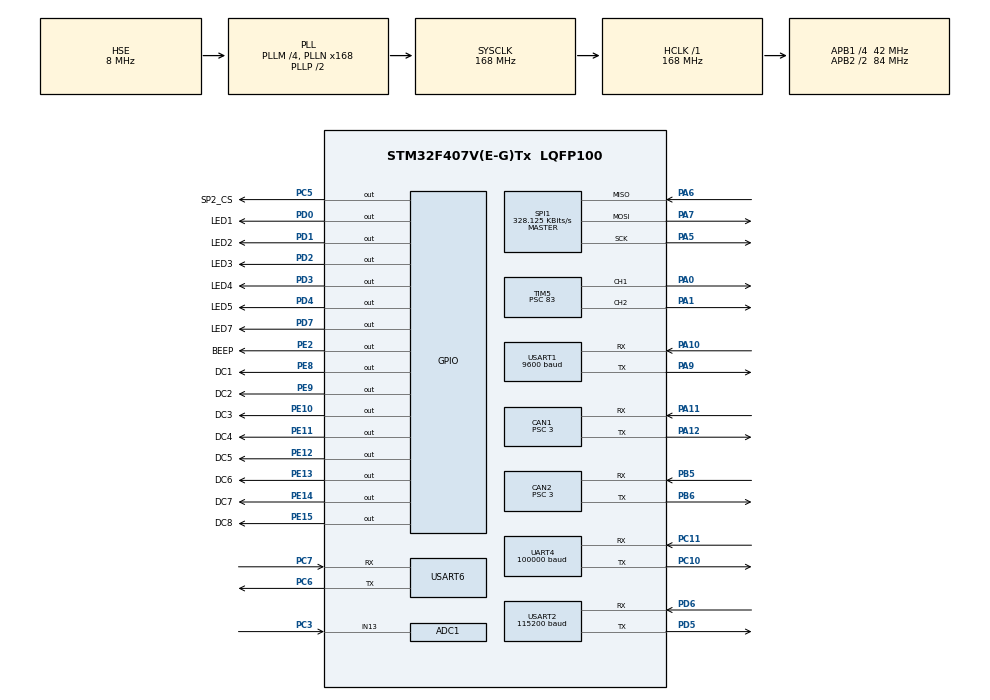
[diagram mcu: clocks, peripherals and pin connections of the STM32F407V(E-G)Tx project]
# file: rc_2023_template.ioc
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ADC1.Channel-0\#ChannelRegularConversion=ADC_CHANNEL_13
ADC1.ContinuousConvMode=DISABLE
ADC1.DMAContinuousRequests=DISABLE
ADC1.NbrOfConversionFlag=1
ADC1.Rank-0\#ChannelRegularConversion=1
ADC1.SamplingTime-0\#ChannelRegularConversion=ADC_SAMPLETIME_3CYCLES
ADC1.master=1
CAN1.ABOM=ENABLE
CAN1.BS1=CAN_BS1_9TQ
CAN1.BS2=CAN_BS2_4TQ
CAN1.CalculateBaudRate=1000000
CAN1.CalculateTimeBit=1000
CAN1.CalculateTimeQuantum=71.42857142857143
CAN1.NART=ENABLE
CAN1.Prescaler=3
CAN2.ABOM=ENABLE
CAN2.BS1=CAN_BS1_9TQ
CAN2.BS2=CAN_BS2_4TQ
CAN2.CalculateBaudRate=1000000
CAN2.CalculateTimeBit=1000
CAN2.CalculateTimeQuantum=71.42857142857143
CAN2.NART=ENABLE
CAN2.Prescaler=3
Dma.Request0=USART1_RX
Dma.Request1=USART1_TX
Dma.Request2=UART4_RX
Dma.Request3=USART2_RX
Dma.Request4=USART2_TX
Dma.Request5=USART6_RX
Dma.Request6=USART6_TX
Dma.UART4_RX.2.Direction=DMA_PERIPH_TO_MEMORY
Dma.UART4_RX.2.FIFOMode=DMA_FIFOMODE_DISABLE
Dma.UART4_RX.2.Instance=DMA1_Stream2
Dma.UART4_RX.2.MemDataAlignment=DMA_MDATAALIGN_BYTE
Dma.UART4_RX.2.MemInc=DMA_MINC_ENABLE
Dma.UART4_RX.2.Mode=DMA_CIRCULAR
Dma.UART4_RX.2.PeriphDataAlignment=DMA_PDATAALIGN_BYTE
Dma.UART4_RX.2.PeriphInc=DMA_PINC_DISABLE
Dma.UART4_RX.2.Priority=DMA_PRIORITY_VERY_HIGH
Dma.USART1_RX.0.Direction=DMA_PERIPH_TO_MEMORY
Dma.USART1_RX.0.FIFOMode=DMA_FIFOMODE_DISABLE
Dma.USART1_RX.0.Instance=DMA2_Stream2
Dma.USART1_RX.0.MemDataAlignment=DMA_MDATAALIGN_BYTE
Dma.USART1_RX.0.MemInc=DMA_MINC_ENABLE
Dma.USART1_RX.0.Mode=DMA_CIRCULAR
Dma.USART1_RX.0.PeriphDataAlignment=DMA_PDATAALIGN_BYTE
Dma.USART1_RX.0.PeriphInc=DMA_PINC_DISABLE
Dma.USART1_RX.0.Priority=DMA_PRIORITY_VERY_HIGH
Dma.USART1_TX.1.Direction=DMA_MEMORY_TO_PERIPH
Dma.USART1_TX.1.FIFOMode=DMA_FIFOMODE_DISABLE
Dma.USART1_TX.1.Instance=DMA2_Stream7
Dma.USART1_TX.1.MemDataAlignment=DMA_MDATAALIGN_BYTE
Dma.USART1_TX.1.MemInc=DMA_MINC_ENABLE
Dma.USART1_TX.1.Mode=DMA_NORMAL
Dma.USART1_TX.1.PeriphDataAlignment=DMA_PDATAALIGN_BYTE
Dma.USART1_TX.1.PeriphInc=DMA_PINC_DISABLE
Dma.USART1_TX.1.Priority=DMA_PRIORITY_HIGH
Dma.USART2_RX.3.Direction=DMA_PERIPH_TO_MEMORY
Dma.USART2_RX.3.FIFOMode=DMA_FIFOMODE_DISABLE
Dma.USART2_RX.3.Instance=DMA1_Stream5
Dma.USART2_RX.3.MemDataAlignment=DMA_MDATAALIGN_BYTE
Dma.USART2_RX.3.MemInc=DMA_MINC_ENABLE
Dma.USART2_RX.3.Mode=DMA_CIRCULAR
Dma.USART2_RX.3.PeriphDataAlignment=DMA_PDATAALIGN_BYTE
Dma.USART2_RX.3.PeriphInc=DMA_PINC_DISABLE
Dma.USART2_RX.3.Priority=DMA_PRIORITY_VERY_HIGH
Dma.USART2_TX.4.Direction=DMA_MEMORY_TO_PERIPH
Dma.USART2_TX.4.FIFOMode=DMA_FIFOMODE_DISABLE
Dma.USART2_TX.4.Instance=DMA1_Stream6
Dma.USART2_TX.4.MemDataAlignment=DMA_MDATAALIGN_BYTE
Dma.USART2_TX.4.MemInc=DMA_MINC_ENABLE
Dma.USART2_TX.4.Mode=DMA_NORMAL
Dma.USART2_TX.4.PeriphDataAlignment=DMA_PDATAALIGN_BYTE
Dma.USART2_TX.4.PeriphInc=DMA_PINC_DISABLE
Dma.USART2_TX.4.Priority=DMA_PRIORITY_HIGH
Dma.USART6_RX.5.Direction=DMA_PERIPH_TO_MEMORY
Dma.USART6_RX.5.FIFOMode=DMA_FIFOMODE_DISABLE
Dma.USART6_RX.5.Instance=DMA2_Stream1
Dma.USART6_RX.5.MemDataAlignment=DMA_MDATAALIGN_BYTE
Dma.USART6_RX.5.MemInc=DMA_MINC_ENABLE
Dma.USART6_RX.5.Mode=DMA_NORMAL
Dma.USART6_RX.5.PeriphDataAlignment=DMA_PDATAALIGN_BYTE
Dma.USART6_RX.5.PeriphInc=DMA_PINC_DISABLE
Dma.USART6_RX.5.Priority=DMA_PRIORITY_VERY_HIGH
Dma.USART6_TX.6.Direction=DMA_MEMORY_TO_PERIPH
Dma.USART6_TX.6.FIFOMode=DMA_FIFOMODE_DISABLE
Dma.USART6_TX.6.Instance=DMA2_Stream6
Dma.USART6_TX.6.MemDataAlignment=DMA_MDATAALIGN_BYTE
Dma.USART6_TX.6.MemInc=DMA_MINC_ENABLE
Dma.USART6_TX.6.Mode=DMA_NORMAL
Dma.USART6_TX.6.PeriphDataAlignment=DMA_PDATAALIGN_BYTE
Dma.USART6_TX.6.PeriphInc=DMA_PINC_DISABLE
Dma.USART6_TX.6.Priority=DMA_PRIORITY_HIGH
FREERTOS.INCLUDE_eTaskGetState=1
FREERTOS.INCLUDE_vTaskDelayUntil=1
FREERTOS.Tasks01=defaultTask,0,128,StartDefaultTask,Default,NULL,Dynamic,NULL,NULL
FREERTOS.configGENERATE_RUN_TIME_STATS=0
FREERTOS.configMINIMAL_STACK_SIZE=64
FREERTOS.configUSE_IDLE_HOOK=1
FREERTOS.configUSE_TRACE_FACILITY=1
Mcu.Family=STM32F4
Mcu.Name=STM32F407V(E-G)Tx
Mcu.Package=LQFP100
NVIC.CAN1_RX0_IRQn=true\:5\:0\:false\:false\:true\:true\:true\:true\:true
NVIC.CAN1_RX1_IRQn=true\:5\:0\:false\:false\:true\:true\:true\:true\:true
NVIC.CAN2_RX0_IRQn=true\:5\:0\:false\:false\:true\:true\:true\:true\:true
NVIC.CAN2_RX1_IRQn=true\:5\:0\:false\:false\:true\:true\:true\:true\:true
NVIC.DMA1_Stream2_IRQn=true\:5\:0\:false\:false\:true\:true\:false\:true\:true
NVIC.DMA1_Stream5_IRQn=true\:5\:0\:false\:false\:true\:true\:false\:true\:true
NVIC.DMA1_Stream6_IRQn=true\:5\:0\:false\:false\:true\:true\:false\:true\:true
NVIC.DMA2_Stream1_IRQn=true\:5\:0\:false\:false\:true\:true\:false\:true\:true
NVIC.DMA2_Stream2_IRQn=true\:5\:0\:false\:false\:true\:true\:false\:true\:true
NVIC.DMA2_Stream6_IRQn=true\:5\:0\:false\:false\:true\:true\:false\:true\:true
NVIC.DMA2_Stream7_IRQn=true\:5\:0\:false\:false\:true\:true\:false\:true\:true
NVIC.PriorityGroup=NVIC_PRIORITYGROUP_4
NVIC.TIM1_UP_TIM10_IRQn=true\:5\:0\:false\:false\:true\:true\:true\:true\:true
NVIC.TIM6_DAC_IRQn=true\:15\:0\:false\:false\:true\:false\:false\:true\:true
NVIC.TIM7_IRQn=true\:5\:0\:true\:false\:true\:true\:true\:true\:true
NVIC.TimeBase=TIM6_DAC_IRQn
NVIC.TimeBaseIP=TIM6
NVIC.UART4_IRQn=true\:5\:0\:false\:false\:true\:true\:true\:true\:true
NVIC.USART1_IRQn=true\:5\:0\:true\:false\:true\:true\:true\:true\:true
NVIC.USART2_IRQn=true\:5\:0\:false\:false\:true\:true\:true\:true\:true
NVIC.USART6_IRQn=true\:5\:0\:false\:false\:true\:true\:true\:true\:true
PA0-WKUP.Signal=S_TIM5_CH1
PA1.Signal=S_TIM5_CH2
PA10.Mode=Asynchronous
PA10.Signal=USART1_RX
PA11.Mode=CAN_Activate
PA11.Signal=CAN1_RX
PA12.Mode=CAN_Activate
PA12.Signal=CAN1_TX
PA13.Mode=Serial_Wire
PA13.Signal=SYS_JTMS-SWDIO
PA14.Mode=Serial_Wire
PA14.Signal=SYS_JTCK-SWCLK
PA5.Mode=Full_Duplex_Master
PA5.Signal=SPI1_SCK
PA6.Mode=Full_Duplex_Master
PA6.Signal=SPI1_MISO
PA7.Mode=Full_Duplex_Master
PA7.Signal=SPI1_MOSI
PA9.Mode=Asynchronous
PA9.Signal=USART1_TX
PB5.Mode=CAN_Activate
PB5.Signal=CAN2_RX
PB6.Mode=CAN_Activate
PB6.Signal=CAN2_TX
PC10.Mode=Asynchronous
PC10.Signal=UART4_TX
PC11.GPIO_PuPd=GPIO_PULLUP
PC11.GPIO_Speed=GPIO_SPEED_FREQ_VERY_HIGH
PC11.Mode=Asynchronous
PC11.Signal=UART4_RX
PC3.Signal=ADCx_IN13
PC5.GPIO_Label=SP2_CS
PC5.GPIO_ModeDefaultOutputPP=GPIO_MODE_OUTPUT_PP
PC5.GPIO_PuPd=GPIO_PULLUP
PC5.GPIO_Speed=GPIO_SPEED_FREQ_HIGH
PC5.PinState=GPIO_PIN_RESET
PC5.Signal=GPIO_Output
PC6.Mode=Asynchronous
PC6.Signal=USART6_TX
PC7.Mode=Asynchronous
PC7.Signal=USART6_RX
PD0.GPIO_Label=LED1
PD0.GPIO_PuPd=GPIO_PULLUP
PD0.GPIO_Speed=GPIO_SPEED_FREQ_HIGH
PD0.PinState=GPIO_PIN_SET
PD0.Signal=GPIO_Output
PD1.GPIO_Label=LED2
PD1.GPIO_PuPd=GPIO_PULLUP
PD1.GPIO_Speed=GPIO_SPEED_FREQ_HIGH
PD1.PinState=GPIO_PIN_SET
PD1.Signal=GPIO_Output
PD2.GPIO_Label=LED3
PD2.GPIO_PuPd=GPIO_PULLUP
PD2.GPIO_Speed=GPIO_SPEED_FREQ_HIGH
PD2.PinState=GPIO_PIN_SET
PD2.Signal=GPIO_Output
PD3.GPIO_Label=LED4
PD3.GPIO_PuPd=GPIO_PULLUP
PD3.GPIO_Speed=GPIO_SPEED_FREQ_HIGH
PD3.PinState=GPIO_PIN_SET
PD3.Signal=GPIO_Output
PD4.GPIO_Label=LED5
PD4.GPIO_ModeDefaultOutputPP=GPIO_MODE_OUTPUT_PP
PD4.GPIO_PuPd=GPIO_PULLUP
PD4.GPIO_Speed=GPIO_SPEED_FREQ_HIGH
PD4.PinState=GPIO_PIN_SET
PD4.Signal=GPIO_Output
PD5.Mode=Asynchronous
PD5.Signal=USART2_TX
PD6.Mode=Asynchronous
PD6.Signal=USART2_RX
PD7.GPIO_Label=LED7
PD7.GPIO_ModeDefaultOutputPP=GPIO_MODE_OUTPUT_PP
PD7.GPIO_PuPd=GPIO_PULLUP
PD7.GPIO_Speed=GPIO_SPEED_FREQ_HIGH
PD7.PinState=GPIO_PIN_SET
PD7.Signal=GPIO_Output
PE10.GPIO_Label=DC3
PE10.GPIO_ModeDefaultOutputPP=GPIO_MODE_OUTPUT_PP
PE10.GPIO_PuPd=GPIO_PULLUP
PE10.GPIO_Speed=GPIO_SPEED_FREQ_HIGH
PE10.PinState=GPIO_PIN_SET
PE10.Signal=GPIO_Output
PE11.GPIO_Label=DC4
PE11.GPIO_ModeDefaultOutputPP=GPIO_MODE_OUTPUT_PP
PE11.GPIO_PuPd=GPIO_PULLUP
PE11.GPIO_Speed=GPIO_SPEED_FREQ_HIGH
PE11.PinState=GPIO_PIN_SET
PE11.Signal=GPIO_Output
PE12.GPIO_Label=DC5
PE12.GPIO_ModeDefaultOutputPP=GPIO_MODE_OUTPUT_PP
PE12.GPIO_PuPd=GPIO_PULLUP
PE12.GPIO_Speed=GPIO_SPEED_FREQ_HIGH
PE12.PinState=GPIO_PIN_SET
PE12.Signal=GPIO_Output
PE13.GPIO_Label=DC6
PE13.GPIO_ModeDefaultOutputPP=GPIO_MODE_OUTPUT_PP
PE13.GPIO_PuPd=GPIO_PULLUP
PE13.GPIO_Speed=GPIO_SPEED_FREQ_HIGH
PE13.PinState=GPIO_PIN_SET
PE13.Signal=GPIO_Output
PE14.GPIO_Label=DC7
PE14.GPIO_ModeDefaultOutputPP=GPIO_MODE_OUTPUT_PP
PE14.GPIO_PuPd=GPIO_PULLUP
PE14.GPIO_Speed=GPIO_SPEED_FREQ_HIGH
PE14.PinState=GPIO_PIN_SET
PE14.Signal=GPIO_Output
PE15.GPIO_Label=DC8
PE15.GPIO_ModeDefaultOutputPP=GPIO_MODE_OUTPUT_PP
PE15.GPIO_PuPd=GPIO_PULLUP
PE15.GPIO_Speed=GPIO_SPEED_FREQ_HIGH
PE15.PinState=GPIO_PIN_SET
PE15.Signal=GPIO_Output
PE2.GPIO_Label=BEEP
PE2.GPIO_PuPd=GPIO_PULLUP
PE2.GPIO_Speed=GPIO_SPEED_FREQ_HIGH
PE2.PinState=GPIO_PIN_RESET
PE2.Signal=GPIO_Output
PE8.GPIO_Label=DC1
PE8.GPIO_ModeDefaultOutputPP=GPIO_MODE_OUTPUT_PP
PE8.GPIO_PuPd=GPIO_PULLUP
PE8.GPIO_Speed=GPIO_SPEED_FREQ_HIGH
PE8.PinState=GPIO_PIN_SET
PE8.Signal=GPIO_Output
PE9.GPIO_Label=DC2
PE9.GPIO_ModeDefaultOutputPP=GPIO_MODE_OUTPUT_PP
PE9.GPIO_PuPd=GPIO_PULLUP
PE9.GPIO_Speed=GPIO_SPEED_FREQ_HIGH
PE9.PinState=GPIO_PIN_SET
PE9.Signal=GPIO_Output
PH0-OSC_IN.Mode=HSE-External-Oscillator
PH0-OSC_IN.Signal=RCC_OSC_IN
PH1-OSC_OUT.Mode=HSE-External-Oscillator
PH1-OSC_OUT.Signal=RCC_OSC_OUT
ProjectManager.HeapSize=0x200
ProjectManager.StackSize=0x400
ProjectManager.TargetToolchain=MDK-ARM V5.32
RCC.48MHZClocksFreq_Value=84000000
RCC.AHBFreq_Value=168000000
RCC.APB1CLKDivider=RCC_HCLK_DIV4
RCC.APB1Freq_Value=42000000
RCC.APB1TimFreq_Value=84000000
RCC.APB2CLKDivider=RCC_HCLK_DIV2
RCC.APB2Freq_Value=84000000
RCC.APB2TimFreq_Value=168000000
RCC.CortexFreq_Value=168000000
RCC.HCLKFreq_Value=168000000
RCC.HSE_VALUE=8000000
RCC.HSI_VALUE=16000000
RCC.LSE_VALUE=32768
RCC.PLLM=4
RCC.PLLN=168
RCC.PLLSourceVirtual=RCC_PLLSOURCE_HSE
RCC.SYSCLKFreq_VALUE=168000000
RCC.SYSCLKSource=RCC_SYSCLKSOURCE_PLLCLK
RCC.VCOOutputFreq_Value=336000000
SH.ADCx_IN13.0=ADC1_IN13,IN13
SH.S_TIM5_CH1.0=TIM5_CH1,PWM Generation1 CH1
SH.S_TIM5_CH2.0=TIM5_CH2,PWM Generation2 CH2
SPI1.BaudRatePrescaler=SPI_BAUDRATEPRESCALER_256
SPI1.CLKPolarity=SPI_POLARITY_HIGH
SPI1.CalculateBaudRate=328.125 KBits/s
SPI1.Direction=SPI_DIRECTION_2LINES
SPI1.FirstBit=SPI_FIRSTBIT_LSB
SPI1.Mode=SPI_MODE_MASTER
SPI1.VirtualType=VM_MASTER
STMicroelectronics.X-CUBE-ALGOBUILD.1.3.0.LibraryCcDSPOoLibraryJjDSPOoLibrary=true
TIM10.Period=999
TIM10.Prescaler=16799
TIM5.Channel-PWM\ Generation1\ CH1=TIM_CHANNEL_1
TIM5.Channel-PWM\ Generation2\ CH2=TIM_CHANNEL_2
TIM5.Period=4999
TIM5.Prescaler=83
TIM7.Period=65535
TIM7.Prescaler=83
UART4.BaudRate=100000
UART4.Mode=MODE_RX
UART4.Parity=PARITY_EVEN
UART4.VirtualMode=Asynchronous
USART1.BaudRate=9600
USART1.VirtualMode=VM_ASYNC
USART2.BaudRate=115200
USART2.Mode=MODE_TX_RX
USART2.VirtualMode=VM_ASYNC
USART6.VirtualMode=VM_ASYNC
VP_CRC_VS_CRC.Mode=CRC_Activate
VP_FREERTOS_VS_CMSIS_V1.Mode=CMSIS_V1
VP_STMicroelectronics.X-CUBE-ALGOBUILD_VS_DSPOoLibraryJjLibrary_1.3.0_1.3.0.Mode=DSPOoLibraryJjLibrary
VP_SYS_VS_tim6.Mode=TIM6
VP_TIM10_VS_ClockSourceINT.Mode=Enable_Timer
VP_TIM5_VS_ClockSourceINT.Mode=Internal
VP_TIM7_VS_ClockSourceINT.Mode=Enable_Timer
board=custom

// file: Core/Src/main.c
/* USER CODE BEGIN Header */
/**
  ******************************************************************************
  * @file           : main.c
  * @brief          : Main program body
  ******************************************************************************
  * @attention
  *
  * Copyright (c) 2023 STMicroelectronics.
  * All rights reserved.
  *
  * This software is licensed under terms that can be found in the LICENSE file
  * in the root directory of this software component.
  * If no LICENSE file comes with this software, it is provided AS-IS.
  *
  ******************************************************************************
  */
/* USER CODE END Header */
#include "main.h"
#include "cmsis_os.h"

/* USER CODE BEGIN Includes */
#include "system_start.h"
/* USER CODE END Includes */

ADC_HandleTypeDef hadc1;

CAN_HandleTypeDef hcan1;
CAN_HandleTypeDef hcan2;

CRC_HandleTypeDef hcrc;

osThreadId defaultTaskHandle;

void SystemClock_Config(void);
static void MX_GPIO_Init(void);
static void MX_DMA_Init(void);
static void MX_UART4_Init(void);
static void MX_TIM7_Init(void);
static void MX_CAN1_Init(void);
static void MX_CAN2_Init(void);
static void MX_USART1_UART_Init(void);
static void MX_CRC_Init(void);
static void MX_USART2_UART_Init(void);
static void MX_TIM5_Init(void);
static void MX_SPI1_Init(void);
static void MX_ADC1_Init(void);
static void MX_USART6_UART_Init(void);
static void MX_TIM10_Init(void);
void StartDefaultTask(void const * argument);

int main(void)
{

  /* MCU Configuration--------------------------------------------------------*/

  /* Reset of all peripherals, Initializes the Flash interface and the Systick. */
  HAL_Init();

  /* Configure the system clock */
  SystemClock_Config();

  /* Initialize all configured peripherals */
  MX_GPIO_Init();
  MX_DMA_Init();
  MX_UART4_Init();
  MX_TIM7_Init();
  MX_CAN1_Init();
  MX_CAN2_Init();
  MX_USART1_UART_Init();
  MX_CRC_Init();
  MX_USART2_UART_Init();
  MX_TIM5_Init();
  MX_SPI1_Init();
  MX_ADC1_Init();
  MX_USART6_UART_Init();
  MX_TIM10_Init();
  /* USER CODE BEGIN 2 */
	System_Init();
  /* USER CODE END 2 */

  /* Create the thread(s) */
  /* definition and creation of defaultTask */
  osThreadDef(defaultTask, StartDefaultTask, osPriorityNormal, 0, 128);
  defaultTaskHandle = osThreadCreate(osThread(defaultTask), NULL);

  /* Start scheduler */
  osKernelStart();

  /* We should never get here as control is now taken by the scheduler */
  /* Infinite loop */
  while (1)
  {

  }
}

void SystemClock_Config(void)
{
  RCC_OscInitTypeDef RCC_OscInitStruct = {0};
  RCC_ClkInitTypeDef RCC_ClkInitStruct = {0};

  /** Configure the main internal regulator output voltage
  */
  __HAL_RCC_PWR_CLK_ENABLE();
  __HAL_PWR_VOLTAGESCALING_CONFIG(PWR_REGULATOR_VOLTAGE_SCALE1);

  /** Initializes the RCC Oscillators according to the specified parameters
  * in the RCC_OscInitTypeDef structure.
  */
  RCC_OscInitStruct.OscillatorType = RCC_OSCILLATORTYPE_HSE;
  RCC_OscInitStruct.HSEState = RCC_HSE_ON;
  RCC_OscInitStruct.PLL.PLLState = RCC_PLL_ON;
  RCC_OscInitStruct.PLL.PLLSource = RCC_PLLSOURCE_HSE;
  RCC_OscInitStruct.PLL.PLLM = 4;
  RCC_OscInitStruct.PLL.PLLN = 168;
  RCC_OscInitStruct.PLL.PLLP = RCC_PLLP_DIV2;
  RCC_OscInitStruct.PLL.PLLQ = 4;
  if (HAL_RCC_OscConfig(&RCC_OscInitStruct) != HAL_OK)
  {
    Error_Handler();
  }

  /** Initializes the CPU, AHB and APB buses clocks
  */
  RCC_ClkInitStruct.ClockType = RCC_CLOCKTYPE_HCLK|RCC_CLOCKTYPE_SYSCLK
                              |RCC_CLOCKTYPE_PCLK1|RCC_CLOCKTYPE_PCLK2;
  RCC_ClkInitStruct.SYSCLKSource = RCC_SYSCLKSOURCE_PLLCLK;
  RCC_ClkInitStruct.AHBCLKDivider = RCC_SYSCLK_DIV1;
  RCC_ClkInitStruct.APB1CLKDivider = RCC_HCLK_DIV4;
  RCC_ClkInitStruct.APB2CLKDivider = RCC_HCLK_DIV2;

  if (HAL_RCC_ClockConfig(&RCC_ClkInitStruct, FLASH_LATENCY_5) != HAL_OK)
  {
    Error_Handler();
  }
}

static void MX_ADC1_Init(void)
{

  ADC_ChannelConfTypeDef sConfig = {0};

  /* USER CODE BEGIN ADC1_Init 1 */
	hadc1.Init.ExternalTrigConv = 0;
  /* USER CODE END ADC1_Init 1 */

  /** Configure the global features of the ADC (Clock, Resolution, Data Alignment and number of conversion)
  */
  hadc1.Instance = ADC1;
  hadc1.Init.ClockPrescaler = ADC_CLOCK_SYNC_PCLK_DIV4;
  hadc1.Init.Resolution = ADC_RESOLUTION_12B;
  hadc1.Init.ScanConvMode = DISABLE;
  hadc1.Init.ContinuousConvMode = DISABLE;
  hadc1.Init.DiscontinuousConvMode = DISABLE;
  hadc1.Init.ExternalTrigConvEdge = ADC_EXTERNALTRIGCONVEDGE_NONE;
  hadc1.Init.ExternalTrigConv = ADC_SOFTWARE_START;
  hadc1.Init.DataAlign = ADC_DATAALIGN_RIGHT;
  hadc1.Init.NbrOfConversion = 1;
  hadc1.Init.DMAContinuousRequests = DISABLE;
  hadc1.Init.EOCSelection = ADC_EOC_SINGLE_CONV;
  if (HAL_ADC_Init(&hadc1) != HAL_OK)
  {
    Error_Handler();
  }

  /** Configure for the selected ADC regular channel its corresponding rank in the sequencer and its sample time.
  */
  sConfig.Channel = ADC_CHANNEL_13;
  sConfig.Rank = 1;
  sConfig.SamplingTime = ADC_SAMPLETIME_3CYCLES;
  if (HAL_ADC_ConfigChannel(&hadc1, &sConfig) != HAL_OK)
  {
    Error_Handler();
  }

}

static void MX_CAN1_Init(void)
{

  hcan1.Instance = CAN1;
  hcan1.Init.Prescaler = 3;
  hcan1.Init.Mode = CAN_MODE_NORMAL;
  hcan1.Init.SyncJumpWidth = CAN_SJW_1TQ;
  hcan1.Init.TimeSeg1 = CAN_BS1_9TQ;
  hcan1.Init.TimeSeg2 = CAN_BS2_4TQ;
  hcan1.Init.TimeTriggeredMode = DISABLE;
  hcan1.Init.AutoBusOff = ENABLE;
  hcan1.Init.AutoWakeUp = DISABLE;
  hcan1.Init.AutoRetransmission = ENABLE;
  hcan1.Init.ReceiveFifoLocked = DISABLE;
  hcan1.Init.TransmitFifoPriority = DISABLE;
  if (HAL_CAN_Init(&hcan1) != HAL_OK)
  {
    Error_Handler();
  }

}

static void MX_CAN2_Init(void)
{

  hcan2.Instance = CAN2;
  hcan2.Init.Prescaler = 3;
  hcan2.Init.Mode = CAN_MODE_NORMAL;
  hcan2.Init.SyncJumpWidth = CAN_SJW_1TQ;
  hcan2.Init.TimeSeg1 = CAN_BS1_9TQ;
  hcan2.Init.TimeSeg2 = CAN_BS2_4TQ;
  hcan2.Init.TimeTriggeredMode = DISABLE;
  hcan2.Init.AutoBusOff = ENABLE;
  hcan2.Init.AutoWakeUp = DISABLE;
  hcan2.Init.AutoRetransmission = ENABLE;
  hcan2.Init.ReceiveFifoLocked = DISABLE;
  hcan2.Init.TransmitFifoPriority = DISABLE;
  if (HAL_CAN_Init(&hcan2) != HAL_OK)
  {
    Error_Handler();
  }

}

static void MX_CRC_Init(void)
{

  hcrc.Instance = CRC;
  if (HAL_CRC_Init(&hcrc) != HAL_OK)
  {
    Error_Handler();
  }

}

static void MX_SPI1_Init(void)
{

  LL_SPI_InitTypeDef SPI_InitStruct = {0};

  LL_GPIO_InitTypeDef GPIO_InitStruct = {0};

  /* Peripheral clock enable */
  LL_APB2_GRP1_EnableClock(LL_APB2_GRP1_PERIPH_SPI1);

  LL_AHB1_GRP1_EnableClock(LL_AHB1_GRP1_PERIPH_GPIOA);
  /**SPI1 GPIO Configuration
  PA5   ------> SPI1_SCK
  PA6   ------> SPI1_MISO
  PA7   ------> SPI1_MOSI
  */
  GPIO_InitStruct.Pin = LL_GPIO_PIN_5|LL_GPIO_PIN_6|LL_GPIO_PIN_7;
  GPIO_InitStruct.Mode = LL_GPIO_MODE_ALTERNATE;
  GPIO_InitStruct.Speed = LL_GPIO_SPEED_FREQ_VERY_HIGH;
  GPIO_InitStruct.OutputType = LL_GPIO_OUTPUT_PUSHPULL;
  GPIO_InitStruct.Pull = LL_GPIO_PULL_NO;
  GPIO_InitStruct.Alternate = LL_GPIO_AF_5;
  LL_GPIO_Init(GPIOA, &GPIO_InitStruct);

  /* SPI1 parameter configuration*/
  SPI_InitStruct.TransferDirection = LL_SPI_FULL_DUPLEX;
  SPI_InitStruct.Mode = LL_SPI_MODE_MASTER;
  SPI_InitStruct.DataWidth = LL_SPI_DATAWIDTH_8BIT;
  SPI_InitStruct.ClockPolarity = LL_SPI_POLARITY_HIGH;
  SPI_InitStruct.ClockPhase = LL_SPI_PHASE_1EDGE;
  SPI_InitStruct.NSS = LL_SPI_NSS_SOFT;
  SPI_InitStruct.BaudRate = LL_SPI_BAUDRATEPRESCALER_DIV256;
  SPI_InitStruct.BitOrder = LL_SPI_LSB_FIRST;
  SPI_InitStruct.CRCCalculation = LL_SPI_CRCCALCULATION_DISABLE;
  SPI_InitStruct.CRCPoly = 10;
  LL_SPI_Init(SPI1, &SPI_InitStruct);
  LL_SPI_SetStandard(SPI1, LL_SPI_PROTOCOL_MOTOROLA);

}

static void MX_TIM5_Init(void)
{

  LL_TIM_InitTypeDef TIM_InitStruct = {0};
  LL_TIM_OC_InitTypeDef TIM_OC_InitStruct = {0};

  LL_GPIO_InitTypeDef GPIO_InitStruct = {0};

  /* Peripheral clock enable */
  LL_APB1_GRP1_EnableClock(LL_APB1_GRP1_PERIPH_TIM5);

  TIM_InitStruct.Prescaler = 83;
  TIM_InitStruct.CounterMode = LL_TIM_COUNTERMODE_UP;
  TIM_InitStruct.Autoreload = 4999;
  TIM_InitStruct.ClockDivision = LL_TIM_CLOCKDIVISION_DIV1;
  LL_TIM_Init(TIM5, &TIM_InitStruct);
  LL_TIM_DisableARRPreload(TIM5);
  LL_TIM_SetClockSource(TIM5, LL_TIM_CLOCKSOURCE_INTERNAL);
  LL_TIM_OC_EnablePreload(TIM5, LL_TIM_CHANNEL_CH1);
  TIM_OC_InitStruct.OCMode = LL_TIM_OCMODE_PWM1;
  TIM_OC_InitStruct.OCState = LL_TIM_OCSTATE_DISABLE;
  TIM_OC_InitStruct.OCNState = LL_TIM_OCSTATE_DISABLE;
  TIM_OC_InitStruct.CompareValue = 0;
  TIM_OC_InitStruct.OCPolarity = LL_TIM_OCPOLARITY_HIGH;
  LL_TIM_OC_Init(TIM5, LL_TIM_CHANNEL_CH1, &TIM_OC_InitStruct);
  LL_TIM_OC_DisableFast(TIM5, LL_TIM_CHANNEL_CH1);
  LL_TIM_OC_EnablePreload(TIM5, LL_TIM_CHANNEL_CH2);
  LL_TIM_OC_Init(TIM5, LL_TIM_CHANNEL_CH2, &TIM_OC_InitStruct);
  LL_TIM_OC_DisableFast(TIM5, LL_TIM_CHANNEL_CH2);
  LL_TIM_SetTriggerOutput(TIM5, LL_TIM_TRGO_RESET);
  LL_TIM_DisableMasterSlaveMode(TIM5);
  LL_AHB1_GRP1_EnableClock(LL_AHB1_GRP1_PERIPH_GPIOA);
  /**TIM5 GPIO Configuration
  PA0-WKUP   ------> TIM5_CH1
  PA1   ------> TIM5_CH2
  */
  GPIO_InitStruct.Pin = LL_GPIO_PIN_0|LL_GPIO_PIN_1;
  GPIO_InitStruct.Mode = LL_GPIO_MODE_ALTERNATE;
  GPIO_InitStruct.Speed = LL_GPIO_SPEED_FREQ_LOW;
  GPIO_InitStruct.OutputType = LL_GPIO_OUTPUT_PUSHPULL;
  GPIO_InitStruct.Pull = LL_GPIO_PULL_NO;
  GPIO_InitStruct.Alternate = LL_GPIO_AF_2;
  LL_GPIO_Init(GPIOA, &GPIO_InitStruct);

}

static void MX_TIM7_Init(void)
{

  LL_TIM_InitTypeDef TIM_InitStruct = {0};

  /* Peripheral clock enable */
  LL_APB1_GRP1_EnableClock(LL_APB1_GRP1_PERIPH_TIM7);

  /* TIM7 interrupt Init */
  NVIC_SetPriority(TIM7_IRQn, NVIC_EncodePriority(NVIC_GetPriorityGrouping(),5, 0));
  NVIC_EnableIRQ(TIM7_IRQn);

  TIM_InitStruct.Prescaler = 83;
  TIM_InitStruct.CounterMode = LL_TIM_COUNTERMODE_UP;
  TIM_InitStruct.Autoreload = 65535;
  LL_TIM_Init(TIM7, &TIM_InitStruct);
  LL_TIM_DisableARRPreload(TIM7);
  LL_TIM_SetTriggerOutput(TIM7, LL_TIM_TRGO_RESET);
  LL_TIM_DisableMasterSlaveMode(TIM7);

}

static void MX_TIM10_Init(void)
{

  LL_TIM_InitTypeDef TIM_InitStruct = {0};

  /* Peripheral clock enable */
  LL_APB2_GRP1_EnableClock(LL_APB2_GRP1_PERIPH_TIM10);

  /* TIM10 interrupt Init */
  NVIC_SetPriority(TIM1_UP_TIM10_IRQn, NVIC_EncodePriority(NVIC_GetPriorityGrouping(),5, 0));
  NVIC_EnableIRQ(TIM1_UP_TIM10_IRQn);

  TIM_InitStruct.Prescaler = 16799;
  TIM_InitStruct.CounterMode = LL_TIM_COUNTERMODE_UP;
  TIM_InitStruct.Autoreload = 999;
  TIM_InitStruct.ClockDivision = LL_TIM_CLOCKDIVISION_DIV1;
  LL_TIM_Init(TIM10, &TIM_InitStruct);
  LL_TIM_DisableARRPreload(TIM10);

}

static void MX_UART4_Init(void)
{

  LL_USART_InitTypeDef USART_InitStruct = {0};

  LL_GPIO_InitTypeDef GPIO_InitStruct = {0};

  /* Peripheral clock enable */
  LL_APB1_GRP1_EnableClock(LL_APB1_GRP1_PERIPH_UART4);

  LL_AHB1_GRP1_EnableClock(LL_AHB1_GRP1_PERIPH_GPIOC);
  /**UART4 GPIO Configuration
  PC10   ------> UART4_TX
  PC11   ------> UART4_RX
  */
  GPIO_InitStruct.Pin = LL_GPIO_PIN_10;
  GPIO_InitStruct.Mode = LL_GPIO_MODE_ALTERNATE;
  GPIO_InitStruct.Speed = LL_GPIO_SPEED_FREQ_VERY_HIGH;
  GPIO_InitStruct.OutputType = LL_GPIO_OUTPUT_PUSHPULL;
  GPIO_InitStruct.Pull = LL_GPIO_PULL_NO;
  GPIO_InitStruct.Alternate = LL_GPIO_AF_8;
  LL_GPIO_Init(GPIOC, &GPIO_InitStruct);

  GPIO_InitStruct.Pin = LL_GPIO_PIN_11;
  GPIO_InitStruct.Mode = LL_GPIO_MODE_ALTERNATE;
  GPIO_InitStruct.Speed = LL_GPIO_SPEED_FREQ_VERY_HIGH;
  GPIO_InitStruct.OutputType = LL_GPIO_OUTPUT_PUSHPULL;
  GPIO_InitStruct.Pull = LL_GPIO_PULL_UP;
  GPIO_InitStruct.Alternate = LL_GPIO_AF_8;
  LL_GPIO_Init(GPIOC, &GPIO_InitStruct);

  /* UART4 DMA Init */

  /* UART4_RX Init */
  LL_DMA_SetChannelSelection(DMA1, LL_DMA_STREAM_2, LL_DMA_CHANNEL_4);

  LL_DMA_SetDataTransferDirection(DMA1, LL_DMA_STREAM_2, LL_DMA_DIRECTION_PERIPH_TO_MEMORY);

  LL_DMA_SetStreamPriorityLevel(DMA1, LL_DMA_STREAM_2, LL_DMA_PRIORITY_VERYHIGH);

  LL_DMA_SetMode(DMA1, LL_DMA_STREAM_2, LL_DMA_MODE_CIRCULAR);

  LL_DMA_SetPeriphIncMode(DMA1, LL_DMA_STREAM_2, LL_DMA_PERIPH_NOINCREMENT);

  LL_DMA_SetMemoryIncMode(DMA1, LL_DMA_STREAM_2, LL_DMA_MEMORY_INCREMENT);

  LL_DMA_SetPeriphSize(DMA1, LL_DMA_STREAM_2, LL_DMA_PDATAALIGN_BYTE);

  LL_DMA_SetMemorySize(DMA1, LL_DMA_STREAM_2, LL_DMA_MDATAALIGN_BYTE);

  LL_DMA_DisableFifoMode(DMA1, LL_DMA_STREAM_2);

  /* UART4 interrupt Init */
  NVIC_SetPriority(UART4_IRQn, NVIC_EncodePriority(NVIC_GetPriorityGrouping(),5, 0));
  NVIC_EnableIRQ(UART4_IRQn);

  USART_InitStruct.BaudRate = 100000;
  USART_InitStruct.DataWidth = LL_USART_DATAWIDTH_8B;
  USART_InitStruct.StopBits = LL_USART_STOPBITS_1;
  USART_InitStruct.Parity = LL_USART_PARITY_EVEN;
  USART_InitStruct.TransferDirection = LL_USART_DIRECTION_RX;
  USART_InitStruct.HardwareFlowControl = LL_USART_HWCONTROL_NONE;
  USART_InitStruct.OverSampling = LL_USART_OVERSAMPLING_16;
  LL_USART_Init(UART4, &USART_InitStruct);
  LL_USART_ConfigAsyncMode(UART4);
  LL_USART_Enable(UART4);

}

static void MX_USART1_UART_Init(void)
{

  LL_USART_InitTypeDef USART_InitStruct = {0};

  LL_GPIO_InitTypeDef GPIO_InitStruct = {0};

  /* Peripheral clock enable */
  LL_APB2_GRP1_EnableClock(LL_APB2_GRP1_PERIPH_USART1);

  LL_AHB1_GRP1_EnableClock(LL_AHB1_GRP1_PERIPH_GPIOA);
  /**USART1 GPIO Configuration
  PA9   ------> USART1_TX
  PA10   ------> USART1_RX
  */
  GPIO_InitStruct.Pin = LL_GPIO_PIN_9|LL_GPIO_PIN_10;
  GPIO_InitStruct.Mode = LL_GPIO_MODE_ALTERNATE;
  GPIO_InitStruct.Speed = LL_GPIO_SPEED_FREQ_VERY_HIGH;
  GPIO_InitStruct.OutputType = LL_GPIO_OUTPUT_PUSHPULL;
  GPIO_InitStruct.Pull = LL_GPIO_PULL_NO;
  GPIO_InitStruct.Alternate = LL_GPIO_AF_7;
  LL_GPIO_Init(GPIOA, &GPIO_InitStruct);

  /* USART1 DMA Init */

  /* USART1_RX Init */
  LL_DMA_SetChannelSelection(DMA2, LL_DMA_STREAM_2, LL_DMA_CHANNEL_4);

  LL_DMA_SetDataTransferDirection(DMA2, LL_DMA_STREAM_2, LL_DMA_DIRECTION_PERIPH_TO_MEMORY);

  LL_DMA_SetStreamPriorityLevel(DMA2, LL_DMA_STREAM_2, LL_DMA_PRIORITY_VERYHIGH);

  LL_DMA_SetMode(DMA2, LL_DMA_STREAM_2, LL_DMA_MODE_CIRCULAR);

  LL_DMA_SetPeriphIncMode(DMA2, LL_DMA_STREAM_2, LL_DMA_PERIPH_NOINCREMENT);

  LL_DMA_SetMemoryIncMode(DMA2, LL_DMA_STREAM_2, LL_DMA_MEMORY_INCREMENT);

  LL_DMA_SetPeriphSize(DMA2, LL_DMA_STREAM_2, LL_DMA_PDATAALIGN_BYTE);

  LL_DMA_SetMemorySize(DMA2, LL_DMA_STREAM_2, LL_DMA_MDATAALIGN_BYTE);

  LL_DMA_DisableFifoMode(DMA2, LL_DMA_STREAM_2);

  /* USART1_TX Init */
  LL_DMA_SetChannelSelection(DMA2, LL_DMA_STREAM_7, LL_DMA_CHANNEL_4);

  LL_DMA_SetDataTransferDirection(DMA2, LL_DMA_STREAM_7, LL_DMA_DIRECTION_MEMORY_TO_PERIPH);

  LL_DMA_SetStreamPriorityLevel(DMA2, LL_DMA_STREAM_7, LL_DMA_PRIORITY_HIGH);

  LL_DMA_SetMode(DMA2, LL_DMA_STREAM_7, LL_DMA_MODE_NORMAL);

  LL_DMA_SetPeriphIncMode(DMA2, LL_DMA_STREAM_7, LL_DMA_PERIPH_NOINCREMENT);

  LL_DMA_SetMemoryIncMode(DMA2, LL_DMA_STREAM_7, LL_DMA_MEMORY_INCREMENT);

  LL_DMA_SetPeriphSize(DMA2, LL_DMA_STREAM_7, LL_DMA_PDATAALIGN_BYTE);

  LL_DMA_SetMemorySize(DMA2, LL_DMA_STREAM_7, LL_DMA_MDATAALIGN_BYTE);

  LL_DMA_DisableFifoMode(DMA2, LL_DMA_STREAM_7);

  /* USART1 interrupt Init */
  NVIC_SetPriority(USART1_IRQn, NVIC_EncodePriority(NVIC_GetPriorityGrouping(),5, 0));
  NVIC_EnableIRQ(USART1_IRQn);

  USART_InitStruct.BaudRate = 9600;
  USART_InitStruct.DataWidth = LL_USART_DATAWIDTH_8B;
  USART_InitStruct.StopBits = LL_USART_STOPBITS_1;
  USART_InitStruct.Parity = LL_USART_PARITY_NONE;
  USART_InitStruct.TransferDirection = LL_USART_DIRECTION_TX_RX;
  USART_InitStruct.HardwareFlowControl = LL_USART_HWCONTROL_NONE;
  USART_InitStruct.OverSampling = LL_USART_OVERSAMPLING_16;
  LL_USART_Init(USART1, &USART_InitStruct);
  LL_USART_ConfigAsyncMode(USART1);
  LL_USART_Enable(USART1);

}

static void MX_USART2_UART_Init(void)
{

  LL_USART_InitTypeDef USART_InitStruct = {0};

  LL_GPIO_InitTypeDef GPIO_InitStruct = {0};

  /* Peripheral clock enable */
  LL_APB1_GRP1_EnableClock(LL_APB1_GRP1_PERIPH_USART2);

  LL_AHB1_GRP1_EnableClock(LL_AHB1_GRP1_PERIPH_GPIOD);
  /**USART2 GPIO Configuration
  PD5   ------> USART2_TX
  PD6   ------> USART2_RX
  */
  GPIO_InitStruct.Pin = LL_GPIO_PIN_5|LL_GPIO_PIN_6;
  GPIO_InitStruct.Mode = LL_GPIO_MODE_ALTERNATE;
  GPIO_InitStruct.Speed = LL_GPIO_SPEED_FREQ_VERY_HIGH;
  GPIO_InitStruct.OutputType = LL_GPIO_OUTPUT_PUSHPULL;
  GPIO_InitStruct.Pull = LL_GPIO_PULL_NO;
  GPIO_InitStruct.Alternate = LL_GPIO_AF_7;
  LL_GPIO_Init(GPIOD, &GPIO_InitStruct);

  /* USART2 DMA Init */

  /* USART2_RX Init */
  LL_DMA_SetChannelSelection(DMA1, LL_DMA_STREAM_5, LL_DMA_CHANNEL_4);

  LL_DMA_SetDataTransferDirection(DMA1, LL_DMA_STREAM_5, LL_DMA_DIRECTION_PERIPH_TO_MEMORY);

  LL_DMA_SetStreamPriorityLevel(DMA1, LL_DMA_STREAM_5, LL_DMA_PRIORITY_VERYHIGH);

  LL_DMA_SetMode(DMA1, LL_DMA_STREAM_5, LL_DMA_MODE_CIRCULAR);

  LL_DMA_SetPeriphIncMode(DMA1, LL_DMA_STREAM_5, LL_DMA_PERIPH_NOINCREMENT);

  LL_DMA_SetMemoryIncMode(DMA1, LL_DMA_STREAM_5, LL_DMA_MEMORY_INCREMENT);

  LL_DMA_SetPeriphSize(DMA1, LL_DMA_STREAM_5, LL_DMA_PDATAALIGN_BYTE);

  LL_DMA_SetMemorySize(DMA1, LL_DMA_STREAM_5, LL_DMA_MDATAALIGN_BYTE);

  LL_DMA_DisableFifoMode(DMA1, LL_DMA_STREAM_5);

  /* USART2_TX Init */
  LL_DMA_SetChannelSelection(DMA1, LL_DMA_STREAM_6, LL_DMA_CHANNEL_4);

  LL_DMA_SetDataTransferDirection(DMA1, LL_DMA_STREAM_6, LL_DMA_DIRECTION_MEMORY_TO_PERIPH);

  LL_DMA_SetStreamPriorityLevel(DMA1, LL_DMA_STREAM_6, LL_DMA_PRIORITY_HIGH);

  LL_DMA_SetMode(DMA1, LL_DMA_STREAM_6, LL_DMA_MODE_NORMAL);

  LL_DMA_SetPeriphIncMode(DMA1, LL_DMA_STREAM_6, LL_DMA_PERIPH_NOINCREMENT);

  LL_DMA_SetMemoryIncMode(DMA1, LL_DMA_STREAM_6, LL_DMA_MEMORY_INCREMENT);

  LL_DMA_SetPeriphSize(DMA1, LL_DMA_STREAM_6, LL_DMA_PDATAALIGN_BYTE);

  LL_DMA_SetMemorySize(DMA1, LL_DMA_STREAM_6, LL_DMA_MDATAALIGN_BYTE);

  LL_DMA_DisableFifoMode(DMA1, LL_DMA_STREAM_6);

  /* USART2 interrupt Init */
  NVIC_SetPriority(USART2_IRQn, NVIC_EncodePriority(NVIC_GetPriorityGrouping(),5, 0));
  NVIC_EnableIRQ(USART2_IRQn);

  USART_InitStruct.BaudRate = 115200;
  USART_InitStruct.DataWidth = LL_USART_DATAWIDTH_8B;
  USART_InitStruct.StopBits = LL_USART_STOPBITS_1;
  USART_InitStruct.Parity = LL_USART_PARITY_NONE;
  USART_InitStruct.TransferDirection = LL_USART_DIRECTION_TX_RX;
  USART_InitStruct.HardwareFlowControl = LL_USART_HWCONTROL_NONE;
  USART_InitStruct.OverSampling = LL_USART_OVERSAMPLING_16;
  LL_USART_Init(USART2, &USART_InitStruct);
  LL_USART_ConfigAsyncMode(USART2);
  LL_USART_Enable(USART2);

}

static void MX_USART6_UART_Init(void)
{

  LL_USART_InitTypeDef USART_InitStruct = {0};

  LL_GPIO_InitTypeDef GPIO_InitStruct = {0};

  /* Peripheral clock enable */
  LL_APB2_GRP1_EnableClock(LL_APB2_GRP1_PERIPH_USART6);

  LL_AHB1_GRP1_EnableClock(LL_AHB1_GRP1_PERIPH_GPIOC);
  /**USART6 GPIO Configuration
  PC6   ------> USART6_TX
  PC7   ------> USART6_RX
  */
  GPIO_InitStruct.Pin = LL_GPIO_PIN_6|LL_GPIO_PIN_7;
  GPIO_InitStruct.Mode = LL_GPIO_MODE_ALTERNATE;
  GPIO_InitStruct.Speed = LL_GPIO_SPEED_FREQ_VERY_HIGH;
  GPIO_InitStruct.OutputType = LL_GPIO_OUTPUT_PUSHPULL;
  GPIO_InitStruct.Pull = LL_GPIO_PULL_NO;
  GPIO_InitStruct.Alternate = LL_GPIO_AF_8;
  LL_GPIO_Init(GPIOC, &GPIO_InitStruct);

  /* USART6 DMA Init */

  /* USART6_RX Init */
  LL_DMA_SetChannelSelection(DMA2, LL_DMA_STREAM_1, LL_DMA_CHANNEL_5);

  LL_DMA_SetDataTransferDirection(DMA2, LL_DMA_STREAM_1, LL_DMA_DIRECTION_PERIPH_TO_MEMORY);

  LL_DMA_SetStreamPriorityLevel(DMA2, LL_DMA_STREAM_1, LL_DMA_PRIORITY_VERYHIGH);

  LL_DMA_SetMode(DMA2, LL_DMA_STREAM_1, LL_DMA_MODE_NORMAL);

  LL_DMA_SetPeriphIncMode(DMA2, LL_DMA_STREAM_1, LL_DMA_PERIPH_NOINCREMENT);

  LL_DMA_SetMemoryIncMode(DMA2, LL_DMA_STREAM_1, LL_DMA_MEMORY_INCREMENT);

  LL_DMA_SetPeriphSize(DMA2, LL_DMA_STREAM_1, LL_DMA_PDATAALIGN_BYTE);

  LL_DMA_SetMemorySize(DMA2, LL_DMA_STREAM_1, LL_DMA_MDATAALIGN_BYTE);

  LL_DMA_DisableFifoMode(DMA2, LL_DMA_STREAM_1);

  /* USART6_TX Init */
  LL_DMA_SetChannelSelection(DMA2, LL_DMA_STREAM_6, LL_DMA_CHANNEL_5);

  LL_DMA_SetDataTransferDirection(DMA2, LL_DMA_STREAM_6, LL_DMA_DIRECTION_MEMORY_TO_PERIPH);

  LL_DMA_SetStreamPriorityLevel(DMA2, LL_DMA_STREAM_6, LL_DMA_PRIORITY_HIGH);

  LL_DMA_SetMode(DMA2, LL_DMA_STREAM_6, LL_DMA_MODE_NORMAL);

  LL_DMA_SetPeriphIncMode(DMA2, LL_DMA_STREAM_6, LL_DMA_PERIPH_NOINCREMENT);

  LL_DMA_SetMemoryIncMode(DMA2, LL_DMA_STREAM_6, LL_DMA_MEMORY_INCREMENT);

  LL_DMA_SetPeriphSize(DMA2, LL_DMA_STREAM_6, LL_DMA_PDATAALIGN_BYTE);

  LL_DMA_SetMemorySize(DMA2, LL_DMA_STREAM_6, LL_DMA_MDATAALIGN_BYTE);

  LL_DMA_DisableFifoMode(DMA2, LL_DMA_STREAM_6);

  /* USART6 interrupt Init */
  NVIC_SetPriority(USART6_IRQn, NVIC_EncodePriority(NVIC_GetPriorityGrouping(),5, 0));
  NVIC_EnableIRQ(USART6_IRQn);

  USART_InitStruct.BaudRate = 115200;
  USART_InitStruct.DataWidth = LL_USART_DATAWIDTH_8B;
  USART_InitStruct.StopBits = LL_USART_STOPBITS_1;
  USART_InitStruct.Parity = LL_USART_PARITY_NONE;
  USART_InitStruct.TransferDirection = LL_USART_DIRECTION_TX_RX;
  USART_InitStruct.HardwareFlowControl = LL_USART_HWCONTROL_NONE;
  USART_InitStruct.OverSampling = LL_USART_OVERSAMPLING_16;
  LL_USART_Init(USART6, &USART_InitStruct);
  LL_USART_ConfigAsyncMode(USART6);
  LL_USART_Enable(USART6);

}

static void MX_DMA_Init(void)
{

  /* Init with LL driver */
  /* DMA controller clock enable */
  LL_AHB1_GRP1_EnableClock(LL_AHB1_GRP1_PERIPH_DMA2);
  LL_AHB1_GRP1_EnableClock(LL_AHB1_GRP1_PERIPH_DMA1);

  /* DMA interrupt init */
  /* DMA1_Stream2_IRQn interrupt configuration */
  NVIC_SetPriority(DMA1_Stream2_IRQn, NVIC_EncodePriority(NVIC_GetPriorityGrouping(),5, 0));
  NVIC_EnableIRQ(DMA1_Stream2_IRQn);
  /* DMA1_Stream5_IRQn interrupt configuration */
  NVIC_SetPriority(DMA1_Stream5_IRQn, NVIC_EncodePriority(NVIC_GetPriorityGrouping(),5, 0));
  NVIC_EnableIRQ(DMA1_Stream5_IRQn);
  /* DMA1_Stream6_IRQn interrupt configuration */
  NVIC_SetPriority(DMA1_Stream6_IRQn, NVIC_EncodePriority(NVIC_GetPriorityGrouping(),5, 0));
  NVIC_EnableIRQ(DMA1_Stream6_IRQn);
  /* DMA2_Stream1_IRQn interrupt configuration */
  NVIC_SetPriority(DMA2_Stream1_IRQn, NVIC_EncodePriority(NVIC_GetPriorityGrouping(),5, 0));
  NVIC_EnableIRQ(DMA2_Stream1_IRQn);
  /* DMA2_Stream2_IRQn interrupt configuration */
  NVIC_SetPriority(DMA2_Stream2_IRQn, NVIC_EncodePriority(NVIC_GetPriorityGrouping(),5, 0));
  NVIC_EnableIRQ(DMA2_Stream2_IRQn);
  /* DMA2_Stream6_IRQn interrupt configuration */
  NVIC_SetPriority(DMA2_Stream6_IRQn, NVIC_EncodePriority(NVIC_GetPriorityGrouping(),5, 0));
  NVIC_EnableIRQ(DMA2_Stream6_IRQn);
  /* DMA2_Stream7_IRQn interrupt configuration */
  NVIC_SetPriority(DMA2_Stream7_IRQn, NVIC_EncodePriority(NVIC_GetPriorityGrouping(),5, 0));
  NVIC_EnableIRQ(DMA2_Stream7_IRQn);

}

static void MX_GPIO_Init(void)
{
  GPIO_InitTypeDef GPIO_InitStruct = {0};

  /* GPIO Ports Clock Enable */
  __HAL_RCC_GPIOE_CLK_ENABLE();
  __HAL_RCC_GPIOH_CLK_ENABLE();
  __HAL_RCC_GPIOC_CLK_ENABLE();
  __HAL_RCC_GPIOA_CLK_ENABLE();
  __HAL_RCC_GPIOD_CLK_ENABLE();
  __HAL_RCC_GPIOB_CLK_ENABLE();

  /*Configure GPIO pin Output Level */
  HAL_GPIO_WritePin(BEEP_GPIO_Port, BEEP_Pin, GPIO_PIN_RESET);

  /*Configure GPIO pin Output Level */
  HAL_GPIO_WritePin(SP2_CS_GPIO_Port, SP2_CS_Pin, GPIO_PIN_RESET);

  /*Configure GPIO pin Output Level */
  HAL_GPIO_WritePin(GPIOE, DC1_Pin|DC2_Pin|DC3_Pin|DC4_Pin
                          |DC5_Pin|DC6_Pin|DC7_Pin|DC8_Pin, GPIO_PIN_SET);

  /*Configure GPIO pin Output Level */
  HAL_GPIO_WritePin(GPIOD, LED1_Pin|LED2_Pin|LED3_Pin|LED4_Pin
                          |LED5_Pin|LED7_Pin, GPIO_PIN_SET);

  /*Configure GPIO pins : BEEP_Pin DC1_Pin DC2_Pin DC3_Pin
                           DC4_Pin DC5_Pin DC6_Pin DC7_Pin
                           DC8_Pin */
  GPIO_InitStruct.Pin = BEEP_Pin|DC1_Pin|DC2_Pin|DC3_Pin
                          |DC4_Pin|DC5_Pin|DC6_Pin|DC7_Pin
                          |DC8_Pin;
  GPIO_InitStruct.Mode = GPIO_MODE_OUTPUT_PP;
  GPIO_InitStruct.Pull = GPIO_PULLUP;
  GPIO_InitStruct.Speed = GPIO_SPEED_FREQ_HIGH;
  HAL_GPIO_Init(GPIOE, &GPIO_InitStruct);

  /*Configure GPIO pin : SP2_CS_Pin */
  GPIO_InitStruct.Pin = SP2_CS_Pin;
  GPIO_InitStruct.Mode = GPIO_MODE_OUTPUT_PP;
  GPIO_InitStruct.Pull = GPIO_PULLUP;
  GPIO_InitStruct.Speed = GPIO_SPEED_FREQ_HIGH;
  HAL_GPIO_Init(SP2_CS_GPIO_Port, &GPIO_InitStruct);

  /*Configure GPIO pins : LED1_Pin LED2_Pin LED3_Pin LED4_Pin
                           LED5_Pin LED7_Pin */
  GPIO_InitStruct.Pin = LED1_Pin|LED2_Pin|LED3_Pin|LED4_Pin
                          |LED5_Pin|LED7_Pin;
  GPIO_InitStruct.Mode = GPIO_MODE_OUTPUT_PP;
  GPIO_InitStruct.Pull = GPIO_PULLUP;
  GPIO_InitStruct.Speed = GPIO_SPEED_FREQ_HIGH;
  HAL_GPIO_Init(GPIOD, &GPIO_InitStruct);

}

void StartDefaultTask(void const * argument)
{
  /* USER CODE BEGIN 5 */

  /* Infinite loop */
  for(;;)
  {
		RTOS_Init();
    osThreadTerminate (defaultTaskHandle);
  }
  /* USER CODE END 5 */
}

void HAL_TIM_PeriodElapsedCallback(TIM_HandleTypeDef *htim)
{
  if (htim->Instance == TIM6) {
    HAL_IncTick();
  }
}

void Error_Handler(void)
{
  __disable_irq();
  while (1)
  {
  }
}
